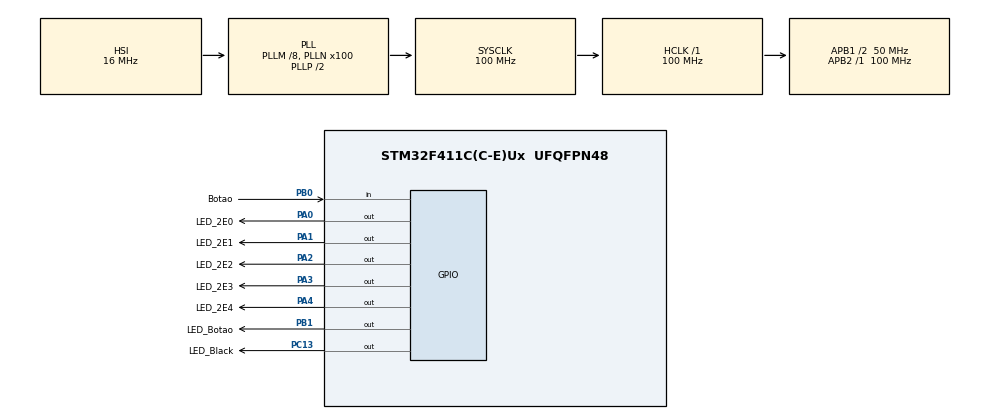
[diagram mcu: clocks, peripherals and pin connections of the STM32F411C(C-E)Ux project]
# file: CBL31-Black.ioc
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Mcu.Family=STM32F4
Mcu.Name=STM32F411C(C-E)Ux
Mcu.Package=UFQFPN48
NVIC.PriorityGroup=NVIC_PRIORITYGROUP_4
PA0-WKUP.GPIO_Label=LED_2E0
PA0-WKUP.Signal=GPIO_Output
PA1.GPIO_Label=LED_2E1
PA1.Signal=GPIO_Output
PA13.Mode=Serial_Wire
PA13.Signal=SYS_JTMS-SWDIO
PA14.Mode=Serial_Wire
PA14.Signal=SYS_JTCK-SWCLK
PA2.GPIO_Label=LED_2E2
PA2.Signal=GPIO_Output
PA3.GPIO_Label=LED_2E3
PA3.Signal=GPIO_Output
PA4.GPIO_Label=LED_2E4
PA4.Signal=GPIO_Output
PB0.GPIO_Label=Botao
PB0.GPIO_PuPd=GPIO_PULLDOWN
PB0.Signal=GPIO_Input
PB1.GPIO_Label=LED_Botao
PB1.Signal=GPIO_Output
PC13-ANTI_TAMP.GPIO_Label=LED_Black
PC13-ANTI_TAMP.Signal=GPIO_Output
PC14-OSC32_IN.Mode=LSE-External-Oscillator
PC14-OSC32_IN.Signal=RCC_OSC32_IN
PC15-OSC32_OUT.Mode=LSE-External-Oscillator
PC15-OSC32_OUT.Signal=RCC_OSC32_OUT
PH0\ -\ OSC_IN.Mode=HSE-External-Oscillator
PH0\ -\ OSC_IN.Signal=RCC_OSC_IN
PH1\ -\ OSC_OUT.Mode=HSE-External-Oscillator
PH1\ -\ OSC_OUT.Signal=RCC_OSC_OUT
ProjectManager.HeapSize=0x200
ProjectManager.StackSize=0x400
ProjectManager.TargetToolchain=STM32CubeIDE
RCC.48MHZClocksFreq_Value=50000000
RCC.AHBFreq_Value=100000000
RCC.APB1CLKDivider=RCC_HCLK_DIV2
RCC.APB1Freq_Value=50000000
RCC.APB1TimFreq_Value=100000000
RCC.APB2Freq_Value=100000000
RCC.APB2TimFreq_Value=100000000
RCC.CortexFreq_Value=100000000
RCC.HCLKFreq_Value=100000000
RCC.HSE_VALUE=25000000
RCC.HSI_VALUE=16000000
RCC.PLLM=8
RCC.PLLN=100
RCC.SYSCLKFreq_VALUE=100000000
RCC.SYSCLKSource=RCC_SYSCLKSOURCE_PLLCLK
RCC.VCOOutputFreq_Value=200000000
board=custom

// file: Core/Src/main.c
/* USER CODE BEGIN Header */
/**
  ******************************************************************************
  * @file           : main.c
  * @brief          : Main program body
  ******************************************************************************
  * @attention
  *
  * Copyright (c) 2026 STMicroelectronics.
  * All rights reserved.
  *
  * This software is licensed under terms that can be found in the LICENSE file
  * in the root directory of this software component.
  * If no LICENSE file comes with this software, it is provided AS-IS.
  *
  ******************************************************************************
  */
/* USER CODE END Header */
#include "main.h"

void SystemClock_Config(void);
static void MX_GPIO_Init(void);

int main(void)
{

  /* USER CODE BEGIN 1 */
	uint16_t CBL = 0;
  /* USER CODE END 1 */

  /* MCU Configuration--------------------------------------------------------*/

  /* Reset of all peripherals, Initializes the Flash interface and the Systick. */
  HAL_Init();

  /* Configure the system clock */
  SystemClock_Config();

  /* Initialize all configured peripherals */
  MX_GPIO_Init();

  /* Infinite loop */
  while (1)
  {
	  //Para que o usuário possa pressionar o botão sem se preocupar com a função HAL_Delay()
	  for(int i=0;i<100/*Caso altere o valor em HAL_Delay, revise aqui*/;i++)
	  {
		  //Caso pressione o botão de incrementar o contador CBL:
		  if(HAL_GPIO_ReadPin(GPIOB, Botao_Pin))
		  {
			  //Ascende um LED indicando que o botão está sendo pressionado:
			  HAL_GPIO_TogglePin(GPIOB,LED_Botao_Pin);

			  //Enquanto não soltar:
			  while ((HAL_GPIO_ReadPin(GPIOB, Botao_Pin))!=0)
			  {
				  //Saídas A,B,C podem ser (des)ativadas ao mesmo tempo ao (des)ativar a soma delas
				  HAL_GPIO_WritePin(GPIOA, ~(CBL+1), 0); //Apaga LEDs ~correspondentes ao contador CBL
				  HAL_GPIO_WritePin(GPIOA, (CBL+1), 1); //Ascende os LEDs correspondentes ao contador CBL
			  }
			  //Apaga o LED que indica o estado do botão ser lido como pressionado:
			  HAL_GPIO_TogglePin(GPIOB, LED_Botao_Pin);

			  CBL==31?CBL=0:CBL++; //Incrementa o contador até resetá-lo quando chegar à 2^5-1
		  }

		  //10ms*100=0,01s*100 = 1s
		  HAL_Delay(10);
	  }

	  //Pisca LED Black (a cada 1 s):
	  HAL_GPIO_TogglePin(GPIOC, LED_Black_Pin);
  }
}

void SystemClock_Config(void)
{
  RCC_OscInitTypeDef RCC_OscInitStruct = {0};
  RCC_ClkInitTypeDef RCC_ClkInitStruct = {0};

  /** Configure the main internal regulator output voltage
  */
  __HAL_RCC_PWR_CLK_ENABLE();
  __HAL_PWR_VOLTAGESCALING_CONFIG(PWR_REGULATOR_VOLTAGE_SCALE1);

  /** Initializes the RCC Oscillators according to the specified parameters
  * in the RCC_OscInitTypeDef structure.
  */
  RCC_OscInitStruct.OscillatorType = RCC_OSCILLATORTYPE_HSI;
  RCC_OscInitStruct.HSIState = RCC_HSI_ON;
  RCC_OscInitStruct.HSICalibrationValue = RCC_HSICALIBRATION_DEFAULT;
  RCC_OscInitStruct.PLL.PLLState = RCC_PLL_ON;
  RCC_OscInitStruct.PLL.PLLSource = RCC_PLLSOURCE_HSI;
  RCC_OscInitStruct.PLL.PLLM = 8;
  RCC_OscInitStruct.PLL.PLLN = 100;
  RCC_OscInitStruct.PLL.PLLP = RCC_PLLP_DIV2;
  RCC_OscInitStruct.PLL.PLLQ = 4;
  if (HAL_RCC_OscConfig(&RCC_OscInitStruct) != HAL_OK)
  {
    Error_Handler();
  }

  /** Initializes the CPU, AHB and APB buses clocks
  */
  RCC_ClkInitStruct.ClockType = RCC_CLOCKTYPE_HCLK|RCC_CLOCKTYPE_SYSCLK
                              |RCC_CLOCKTYPE_PCLK1|RCC_CLOCKTYPE_PCLK2;
  RCC_ClkInitStruct.SYSCLKSource = RCC_SYSCLKSOURCE_PLLCLK;
  RCC_ClkInitStruct.AHBCLKDivider = RCC_SYSCLK_DIV1;
  RCC_ClkInitStruct.APB1CLKDivider = RCC_HCLK_DIV2;
  RCC_ClkInitStruct.APB2CLKDivider = RCC_HCLK_DIV1;

  if (HAL_RCC_ClockConfig(&RCC_ClkInitStruct, FLASH_LATENCY_3) != HAL_OK)
  {
    Error_Handler();
  }
}

static void MX_GPIO_Init(void)
{
  GPIO_InitTypeDef GPIO_InitStruct = {0};

  /* GPIO Ports Clock Enable */
  __HAL_RCC_GPIOC_CLK_ENABLE();
  __HAL_RCC_GPIOH_CLK_ENABLE();
  __HAL_RCC_GPIOA_CLK_ENABLE();
  __HAL_RCC_GPIOB_CLK_ENABLE();

  /*Configure GPIO pin Output Level */
  HAL_GPIO_WritePin(LED_Black_GPIO_Port, LED_Black_Pin, GPIO_PIN_RESET);

  /*Configure GPIO pin Output Level */
  HAL_GPIO_WritePin(GPIOA, LED_2E0_Pin|LED_2E1_Pin|LED_2E2_Pin|LED_2E3_Pin
                          |LED_2E4_Pin, GPIO_PIN_RESET);

  /*Configure GPIO pin Output Level */
  HAL_GPIO_WritePin(LED_Botao_GPIO_Port, LED_Botao_Pin, GPIO_PIN_RESET);

  /*Configure GPIO pin : LED_Black_Pin */
  GPIO_InitStruct.Pin = LED_Black_Pin;
  GPIO_InitStruct.Mode = GPIO_MODE_OUTPUT_PP;
  GPIO_InitStruct.Pull = GPIO_NOPULL;
  GPIO_InitStruct.Speed = GPIO_SPEED_FREQ_LOW;
  HAL_GPIO_Init(LED_Black_GPIO_Port, &GPIO_InitStruct);

  /*Configure GPIO pins : LED_2E0_Pin LED_2E1_Pin LED_2E2_Pin LED_2E3_Pin
                           LED_2E4_Pin */
  GPIO_InitStruct.Pin = LED_2E0_Pin|LED_2E1_Pin|LED_2E2_Pin|LED_2E3_Pin
                          |LED_2E4_Pin;
  GPIO_InitStruct.Mode = GPIO_MODE_OUTPUT_PP;
  GPIO_InitStruct.Pull = GPIO_NOPULL;
  GPIO_InitStruct.Speed = GPIO_SPEED_FREQ_LOW;
  HAL_GPIO_Init(GPIOA, &GPIO_InitStruct);

  /*Configure GPIO pin : Botao_Pin */
  GPIO_InitStruct.Pin = Botao_Pin;
  GPIO_InitStruct.Mode = GPIO_MODE_INPUT;
  GPIO_InitStruct.Pull = GPIO_PULLDOWN;
  HAL_GPIO_Init(Botao_GPIO_Port, &GPIO_InitStruct);

  /*Configure GPIO pin : LED_Botao_Pin */
  GPIO_InitStruct.Pin = LED_Botao_Pin;
  GPIO_InitStruct.Mode = GPIO_MODE_OUTPUT_PP;
  GPIO_InitStruct.Pull = GPIO_NOPULL;
  GPIO_InitStruct.Speed = GPIO_SPEED_FREQ_LOW;
  HAL_GPIO_Init(LED_Botao_GPIO_Port, &GPIO_InitStruct);

}

void Error_Handler(void)
{
  __disable_irq();
  while (1)
  {
  }
}
